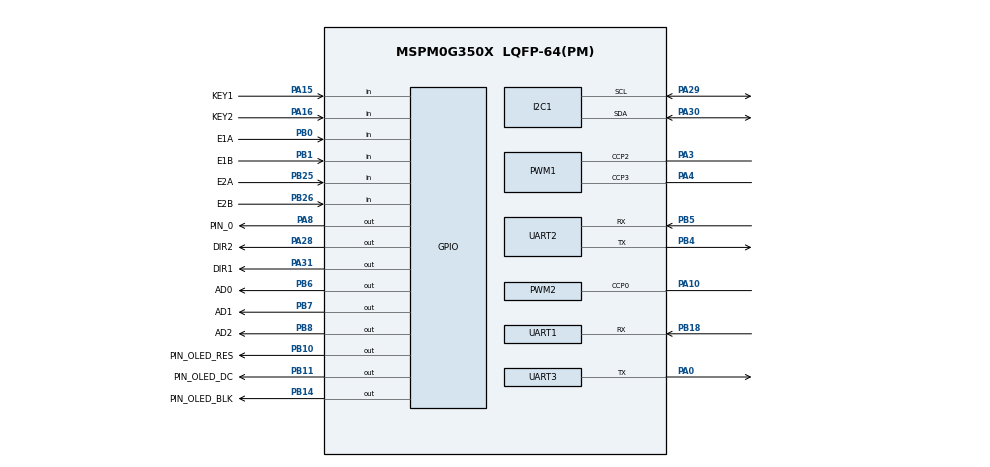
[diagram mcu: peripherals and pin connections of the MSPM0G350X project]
/**
 * @cliArgs --device "MSPM0G350X" --part "Default" --package "LQFP-64(PM)" --product "mspm0_sdk@2.10.00.04"
 * @versions {"tool":"1.26.2+4477"}
 */

/**
 * Import the modules used in this configuration.
 */
const ADC12  = scripting.addModule("/ti/driverlib/ADC12", {}, false);
const ADC121 = ADC12.addInstance();
const GPIO   = scripting.addModule("/ti/driverlib/GPIO", {}, false);
const GPIO1  = GPIO.addInstance();
const GPIO2  = GPIO.addInstance();
const GPIO3  = GPIO.addInstance();
const GPIO4  = GPIO.addInstance();
const GPIO5  = GPIO.addInstance();
const GPIO6  = GPIO.addInstance();
const GPIO7  = GPIO.addInstance();
const I2C    = scripting.addModule("/ti/driverlib/I2C", {}, false);
const I2C1   = I2C.addInstance();
const PWM    = scripting.addModule("/ti/driverlib/PWM", {}, false);
const PWM1   = PWM.addInstance();
const PWM2   = PWM.addInstance();
const SYSCTL = scripting.addModule("/ti/driverlib/SYSCTL");
const TIMER  = scripting.addModule("/ti/driverlib/TIMER", {}, false);
const TIMER1 = TIMER.addInstance();
const UART   = scripting.addModule("/ti/driverlib/UART", {}, false);
const UART1  = UART.addInstance();
const UART2  = UART.addInstance();
const UART3  = UART.addInstance();

/**
 * Write custom configuration values to the imported modules.
 */
const divider7       = system.clockTree["PLL_PDIV"];
divider7.divideValue = 2;

const divider9       = system.clockTree["UDIV"];
divider9.divideValue = 2;

const multiplier2         = system.clockTree["PLL_QDIV"];
multiplier2.multiplyValue = 5;

const mux8       = system.clockTree["HSCLKMUX"];
mux8.inputSelect = "HSCLKMUX_SYSPLL2X";

const pinFunction4       = system.clockTree["HFXT"];
pinFunction4.HFXTStartup = 10;

ADC121.$name                             = "ADC12_0";
ADC121.sampleTime0                       = "2 us";
ADC121.sampClkDiv                        = "DL_ADC12_CLOCK_DIVIDE_8";
ADC121.adcMem0_name                      = "ADC_CH0";
ADC121.repeatMode                        = true;
ADC121.configureDMA                      = true;
ADC121.sampClkSrc                        = "DL_ADC12_CLOCK_ULPCLK";
ADC121.sampCnt                           = 1;
ADC121.enabledDMATriggers                = ["DL_ADC12_DMA_MEM0_RESULT_LOADED"];
ADC121.peripheral.$assign                = "ADC0";
ADC121.peripheral.adcPin0.$assign        = "PA27";
ADC121.adcPin0Config.$name               = "ti_driverlib_gpio_GPIOPinGeneric5";
ADC121.DMA_CHANNEL.$name                 = "DMA_GRAY";
ADC121.DMA_CHANNEL.srcLength             = "HALF_WORD";
ADC121.DMA_CHANNEL.dstLength             = "HALF_WORD";
ADC121.DMA_CHANNEL.addressMode           = "f2b";
ADC121.DMA_CHANNEL.configureTransferSize = true;
ADC121.DMA_CHANNEL.transferSize          = 40;
ADC121.DMA_CHANNEL.transferMode          = "FULL_CH_REPEAT_SINGLE";

const Board = scripting.addModule("/ti/driverlib/Board", {}, false);

GPIO1.$name                         = "KEY";
GPIO1.associatedPins.create(2);
GPIO1.associatedPins[0].$name       = "KEY2";
GPIO1.associatedPins[0].direction   = "INPUT";
GPIO1.associatedPins[0].interruptEn = true;
GPIO1.associatedPins[0].polarity    = "FALL";
GPIO1.associatedPins[0].pin.$assign = "PA16";
GPIO1.associatedPins[1].$name       = "KEY1";
GPIO1.associatedPins[1].direction   = "INPUT";
GPIO1.associatedPins[1].interruptEn = true;
GPIO1.associatedPins[1].polarity    = "FALL";
GPIO1.associatedPins[1].pin.$assign = "PA15";

GPIO2.$name                               = "ENCODERA";
GPIO2.associatedPins.create(2);
GPIO2.associatedPins[0].$name             = "E1A";
GPIO2.associatedPins[0].direction         = "INPUT";
GPIO2.associatedPins[0].interruptEn       = true;
GPIO2.associatedPins[0].interruptPriority = "0";
GPIO2.associatedPins[0].polarity          = "RISE";
GPIO2.associatedPins[0].pin.$assign       = "PB0";
GPIO2.associatedPins[1].$name             = "E1B";
GPIO2.associatedPins[1].direction         = "INPUT";
GPIO2.associatedPins[1].interruptEn       = true;
GPIO2.associatedPins[1].interruptPriority = "0";
GPIO2.associatedPins[1].polarity          = "RISE";
GPIO2.associatedPins[1].pin.$assign       = "PB1";

GPIO3.$name                               = "ENCODERB";
GPIO3.associatedPins.create(2);
GPIO3.associatedPins[0].$name             = "E2A";
GPIO3.associatedPins[0].direction         = "INPUT";
GPIO3.associatedPins[0].interruptEn       = true;
GPIO3.associatedPins[0].interruptPriority = "0";
GPIO3.associatedPins[0].polarity          = "RISE";
GPIO3.associatedPins[0].pin.$assign       = "PB25";
GPIO3.associatedPins[1].$name             = "E2B";
GPIO3.associatedPins[1].direction         = "INPUT";
GPIO3.associatedPins[1].interruptEn       = true;
GPIO3.associatedPins[1].interruptPriority = "0";
GPIO3.associatedPins[1].polarity          = "RISE";
GPIO3.associatedPins[1].pin.$assign       = "PB26";

GPIO4.$name                              = "LED";
GPIO4.associatedPins[0].$name            = "PIN_0";
GPIO4.associatedPins[0].internalResistor = "PULL_DOWN";
GPIO4.associatedPins[0].pin.$assign      = "PA8";

GPIO5.$name                         = "GPIO_OLED";
GPIO5.associatedPins.create(3);
GPIO5.associatedPins[0].$name       = "PIN_OLED_RES";
GPIO5.associatedPins[0].pin.$assign = "PB10";
GPIO5.associatedPins[1].$name       = "PIN_OLED_DC";
GPIO5.associatedPins[1].pin.$assign = "PB11";
GPIO5.associatedPins[2].$name       = "PIN_OLED_BLK";
GPIO5.associatedPins[2].pin.$assign = "PB14";

GPIO6.$name                          = "DIR";
GPIO6.associatedPins.create(2);
GPIO6.associatedPins[0].$name        = "DIR1";
GPIO6.associatedPins[0].assignedPort = "PORTA";
GPIO6.associatedPins[0].assignedPin  = "31";
GPIO6.associatedPins[0].pin.$assign  = "PA31";
GPIO6.associatedPins[1].$name        = "DIR2";
GPIO6.associatedPins[1].assignedPort = "PORTA";
GPIO6.associatedPins[1].assignedPin  = "28";
GPIO6.associatedPins[1].pin.$assign  = "PA28";

GPIO7.$name                         = "Gray_Address";
GPIO7.associatedPins.create(3);
GPIO7.associatedPins[0].$name       = "AD0";
GPIO7.associatedPins[0].pin.$assign = "PB6";
GPIO7.associatedPins[1].$name       = "AD1";
GPIO7.associatedPins[1].pin.$assign = "PB7";
GPIO7.associatedPins[2].$name       = "AD2";
GPIO7.associatedPins[2].pin.$assign = "PB8";

I2C1.$name                             = "I2C_OLED";
I2C1.basicEnableController             = true;
I2C1.basicControllerStandardBusSpeed   = "Fast";
I2C1.peripheral.$assign                = "I2C1";
I2C1.peripheral.sdaPin.$assign         = "PA30";
I2C1.peripheral.sclPin.$assign         = "PA29";
I2C1.sdaPinConfig.hideOutputInversion  = scripting.forceWrite(false);
I2C1.sdaPinConfig.onlyInternalResistor = scripting.forceWrite(false);
I2C1.sdaPinConfig.passedPeripheralType = scripting.forceWrite("Digital");
I2C1.sdaPinConfig.$name                = "ti_driverlib_gpio_GPIOPinGeneric0";
I2C1.sclPinConfig.$name                = "ti_driverlib_gpio_GPIOPinGeneric2";
I2C1.sclPinConfig.hideOutputInversion  = scripting.forceWrite(false);
I2C1.sclPinConfig.onlyInternalResistor = scripting.forceWrite(false);
I2C1.sclPinConfig.passedPeripheralType = scripting.forceWrite("Digital");

PWM1.clockDivider               = 2;
PWM1.timerStartTimer            = true;
PWM1.pwmMode                    = "EDGE_ALIGN_UP";
PWM1.$name                      = "PWMAB";
PWM1.ccIndex                    = [2,3];
PWM1.clockPrescale              = 40;
PWM1.timerCount                 = 100;
PWM1.peripheral.$assign         = "TIMA0";
PWM1.peripheral.ccp2Pin.$assign = "PA3";
PWM1.peripheral.ccp3Pin.$assign = "PA4";
PWM1.PWM_CHANNEL_2.$name        = "ti_driverlib_pwm_PWMTimerCC0";
PWM1.PWM_CHANNEL_3.$name        = "ti_driverlib_pwm_PWMTimerCC2";
PWM1.ccp2PinConfig.$name        = "ti_driverlib_gpio_GPIOPinGeneric8";
PWM1.ccp3PinConfig.$name        = "ti_driverlib_gpio_GPIOPinGeneric6";

PWM2.clockDivider                     = 2;
PWM2.timerStartTimer                  = true;
PWM2.pwmMode                          = "EDGE_ALIGN_UP";
PWM2.$name                            = "PWM_STEPMOTOR";
PWM2.ccIndex                          = [0];
PWM2.clockPrescale                    = 40;
PWM2.timerCount                       = 20000;
PWM2.PWM_CHANNEL_0.$name              = "ti_driverlib_pwm_PWMTimerCC1";
PWM2.PWM_CHANNEL_0.ccValue            = 1499;
PWM2.PWM_CHANNEL_0.shadowUpdateMode   = "ZERO_EVT";
PWM2.ccp0PinConfig.$name              = "ti_driverlib_gpio_GPIOPinGeneric9";
PWM2.peripheral.$assign               = "TIMA1";
PWM2.peripheral.ccp0Pin.$assign       = "PA10";

SYSCTL.forceDefaultClkConfig = true;
SYSCTL.clockTreeEn           = true;

TIMER1.$name              = "TIMER_0";
TIMER1.timerStartTimer    = true;
TIMER1.interrupts         = ["ZERO"];
TIMER1.timerMode          = "PERIODIC";
TIMER1.timerClkDiv        = 8;
TIMER1.timerClkPrescale   = 128;
TIMER1.timerPeriod        = "20 ms";
TIMER1.peripheral.$assign = "TIMG7";

UART1.$name                            = "UART_BNO08X";
UART1.targetBaudRate                   = 115200;
UART1.direction                        = "RX";
UART1.enableFIFO                       = true;
UART1.rxTimeoutValue                   = 1;
UART1.enabledInterrupts                = ["RX_TIMEOUT_ERROR"];
UART1.enabledDMARXTriggers             = "DL_UART_DMA_INTERRUPT_RX";
UART1.rxPinConfig.hideOutputInversion  = scripting.forceWrite(false);
UART1.rxPinConfig.onlyInternalResistor = scripting.forceWrite(false);
UART1.rxPinConfig.passedPeripheralType = scripting.forceWrite("Digital");
UART1.rxPinConfig.$name                = "ti_driverlib_gpio_GPIOPinGeneric1";
UART1.peripheral.$assign               = "UART2";
UART1.peripheral.rxPin.$assign         = "PB18";
UART1.DMA_CHANNEL_RX.addressMode       = "f2b";
UART1.DMA_CHANNEL_RX.srcLength         = "BYTE";
UART1.DMA_CHANNEL_RX.dstLength         = "BYTE";
UART1.DMA_CHANNEL_RX.$name             = "DMA_BNO08X";

UART2.$name                            = "UART_DEBUG";
UART2.targetBaudRate                   = 115200;
UART2.enabledInterrupts                = ["RX"];
UART2.peripheral.$assign               = "UART1";
UART2.peripheral.rxPin.$assign         = "PB5";
UART2.peripheral.txPin.$assign         = "PB4";
UART2.txPinConfig.direction            = scripting.forceWrite("OUTPUT");
UART2.txPinConfig.hideOutputInversion  = scripting.forceWrite(false);
UART2.txPinConfig.onlyInternalResistor = scripting.forceWrite(false);
UART2.txPinConfig.passedPeripheralType = scripting.forceWrite("Digital");
UART2.txPinConfig.$name                = "ti_driverlib_gpio_GPIOPinGeneric3";
UART2.rxPinConfig.hideOutputInversion  = scripting.forceWrite(false);
UART2.rxPinConfig.onlyInternalResistor = scripting.forceWrite(false);
UART2.rxPinConfig.passedPeripheralType = scripting.forceWrite("Digital");
UART2.rxPinConfig.$name                = "ti_driverlib_gpio_GPIOPinGeneric4";

UART3.$name                            = "UART_STEPMOTOR";
UART3.targetBaudRate                   = 115200;
UART3.direction                        = "TX";
UART3.enableFIFO                       = true;
UART3.rxFifoThreshold                  = "DL_UART_RX_FIFO_LEVEL_ONE_ENTRY";
UART3.enableInternalLoopback           = false;
UART3.enableDMARX                      = false;
UART3.enableDMATX                      = false;
UART3.txPinConfig.$name                = "ti_driverlib_gpio_GPIOPinGeneric7";
UART3.txPinConfig.direction            = scripting.forceWrite("OUTPUT");
UART3.txPinConfig.hideOutputInversion  = scripting.forceWrite(false);
UART3.txPinConfig.onlyInternalResistor = scripting.forceWrite(false);
UART3.txPinConfig.passedPeripheralType = scripting.forceWrite("Digital");
UART3.peripheral.$assign               = "UART0";
UART3.peripheral.txPin.$assign         = "PA0";

/**
 * Pinmux solution for unlocked pins/peripherals. This ensures that minor changes to the automatic solver in a future
 * version of the tool will not impact the pinmux you originally saw.  These lines can be completely deleted in order to
 * re-solve from scratch.
 */
ADC121.DMA_CHANNEL.peripheral.$suggestSolution   = "DMA_CH1";
Board.peripheral.$suggestSolution                = "DEBUGSS";
Board.peripheral.swclkPin.$suggestSolution       = "PA20";
Board.peripheral.swdioPin.$suggestSolution       = "PA19";
UART1.DMA_CHANNEL_RX.peripheral.$suggestSolution = "DMA_CH0";
